# MB9AF15xN register map
File version: 1.7
Registers are 32-bit, read-write, reset 0x0 unless marked. A register's access mark holds for its fields unless they carry their own. Offsets are from the block's base; [hi:lo] are bit positions; 'fields as' and 'values as' point back to an identical list.

## CRTRIM — CR Trimming Registers
Base 0x4002E000
0x00 MCR_PSR 8-bit reset 0x1 — High-speed CR oscillation Frequency Division Setup Register
  [1:0] CSR — High-speed CR oscillation frequency division ratio setting bits
0x04 MCR_FTRM 16-bit reset 0x180 — High-speed CR oscillation Frequency Trimming Register
  [9:0] TRD — Frequency trimming setup bits
0x0C MCR_RLR reset 0x1 — High-Speed CR Oscillation Register Write-Protect Register
  [31:0] TRMLCK — Register write-protect bits

## SWWDT — Software Watchdog Timer
Base 0x40012000
0x00 WDOGLOAD reset 0xFFFFFFFF — Software Watchdog Timer Load Register
0x04 WDOGVALUE ro reset 0xFFFFFFFF — Software Watchdog Timer Value Register
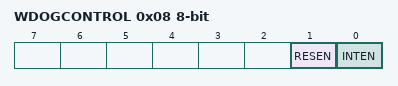
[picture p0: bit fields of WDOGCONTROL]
0x08 WDOGCONTROL 8-bit — Software Watchdog Timer Control Register
  [1] RESEN — Reset enable bit of the software watchdog
  [0] INTEN — Interrupt and counter enable bit of the software watchdog
0x0C WDOGINTCLR reset 0xFFFFFFFF — Software Watchdog Timer Clear Register
0x10 WDOGRIS 8-bit ro — Software Watchdog Timer Interrupt Status Register
  [0] RIS — Software watchdog interrupt status bit
0xC00 WDOGLOCK — Software Watchdog Timer Lock Register

## HWWDT — Hardware Watchdog Timer
Base 0x40011000
0x00 WDG_LDR reset 0xFFFF — Hardware Watchdog Timer Load Register
0x04 WDG_VLR ro — Hardware Watchdog Timer Value Register
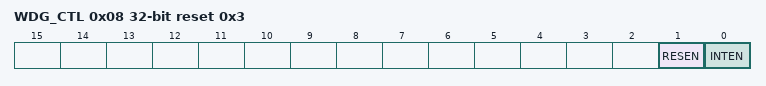
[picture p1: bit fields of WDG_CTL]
0x08 WDG_CTL reset 0x3 — Hardware Watchdog Timer Control Register
  [1] RESEN — Hardware watchdog reset enable bit
  [0] INTEN — Hardware watchdog interrupt and counter enable bit
0x0C WDG_ICL 8-bit reset 0xFF (reset mask 0x0) — Hardware Watchdog Timer Clear Register
0x10 WDG_RIS 1-bit ro reset 0xFF (reset mask 0x0) — Hardware Watchdog Timer Interrupt Status Register
  [0] RIS — Hardware watchdog interrupt status bit
0xC00 WDG_LCK reset 0x1 — Hardware Watchdog Timer Lock Register

## DTIM — Dual Timer
Base 0x40015000
0x00 TIMER1LOAD (DualTimer1 view) — Load Register
0x04 TIMER1VALUE ro reset 0xFFFFFFFF — Value Register
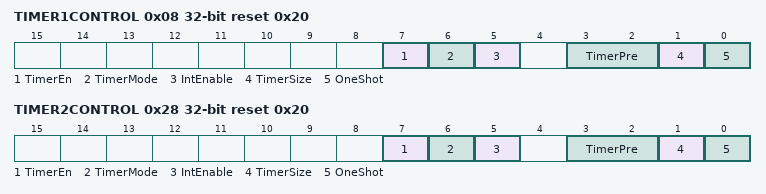
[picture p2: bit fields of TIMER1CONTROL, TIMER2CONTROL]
0x08 TIMER1CONTROL reset 0x20 — Control Register
  [7] TimerEn — Enable bit
  [6] TimerMode — Mode bit
  [5] IntEnable — Interrupt enable bit
  [3:2] TimerPre — Prescale bits
  [1] TimerSize — Counter size bit
  [0] OneShot — One-shot mode bit
0x0C TIMER1INTCLR wo reset not defined — Interrupt Clear Register
0x10 TIMER1RIS ro — Interrupt Status Register
  [0] TIMER1RIS — Interrupt Status Register bit
0x14 TIMER1MIS ro — Masked Interrupt Status Register
  [0] TIMER1MIS — Masked Interrupt Status bit
0x18 TIMER1BGLOAD — Background Load Register
0x20 TIMER2LOAD — Load Register
0x24 TIMER2VALUE ro reset 0xFFFFFFFF — Value Register
0x28 TIMER2CONTROL reset 0x20 — Control Register
  fields as TIMER1CONTROL
0x2C TIMER2INTCLR wo reset not defined — Interrupt Clear Register
0x30 TIMER2RIS ro — Interrupt Status Register
  [0] TIMER1RIS — Interrupt Status Register bit
0x34 TIMER2MIS ro — Masked Interrupt Status Register
  [0] TIMER1MIS — Masked Interrupt Status bit
0x38 TIMER2BGLOAD — Background Load Register

## BTIOSEL03 — Base Timer I/O Select
Base 0x40025100
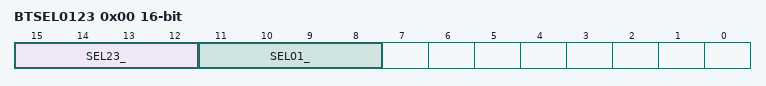
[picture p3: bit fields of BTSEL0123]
0x00 BTSEL0123 16-bit — I/O Select Register
  [15:12] SEL23_ — I/O select bits for Ch.2/Ch.3
  [11:8] SEL01_ — I/O select bits for Ch.0/Ch.1

## BTIOSEL47 — Base Timer I/O Select
Base 0x40025300
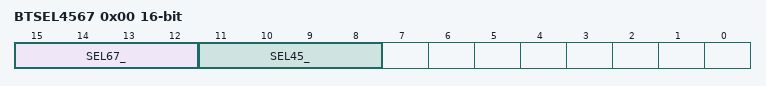
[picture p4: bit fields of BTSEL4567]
0x00 BTSEL4567 16-bit — I/O Select Register
  [15:12] SEL67_ — I/O select bits for Ch.6/Ch.7
  [11:8] SEL45_ — I/O select bits for Ch.4/Ch.5

## BTIOSEL8B — Base Timer I/O Select
Base 0x40025500
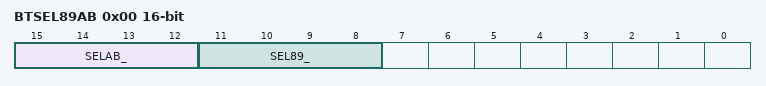
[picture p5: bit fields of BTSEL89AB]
0x00 BTSEL89AB 16-bit — I/O Select Register
  [15:12] SELAB_ — I/O select bits for Ch.A/Ch.B
  [11:8] SEL89_ — I/O select bits for Ch.8/Ch.9

## BTIOSELCF — Base Timer I/O Select
Base 0x40025700
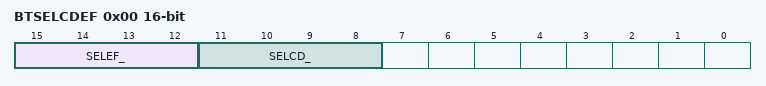
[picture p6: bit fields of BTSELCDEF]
0x00 BTSELCDEF 16-bit — I/O Select Register
  [15:12] SELEF_ — I/O select bits for Ch.E/Ch.F
  [11:8] SELCD_ — I/O select bits for Ch.C/Ch.D
